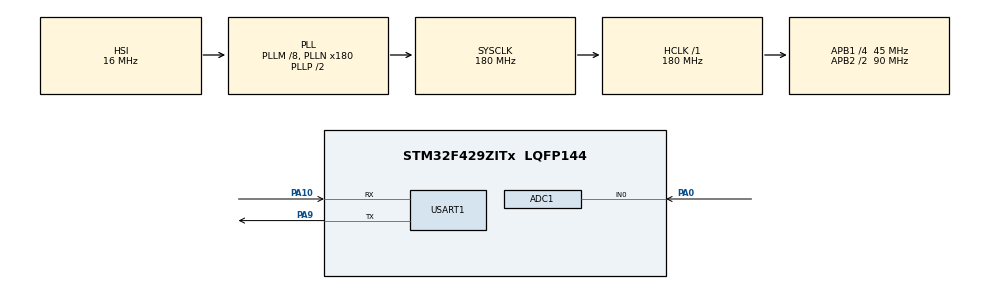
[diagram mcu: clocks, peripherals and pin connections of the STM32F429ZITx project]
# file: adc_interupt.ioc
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ADC1.Channel-0\#ChannelRegularConversion=ADC_CHANNEL_0
ADC1.NbrOfConversionFlag=1
ADC1.Rank-0\#ChannelRegularConversion=1
ADC1.SamplingTime-0\#ChannelRegularConversion=ADC_SAMPLETIME_480CYCLES
ADC1.master=1
Mcu.Family=STM32F4
Mcu.Name=STM32F429ZITx
Mcu.Package=LQFP144
NVIC.ADC_IRQn=true\:0\:0\:false\:false\:true\:true\:true\:true
NVIC.PriorityGroup=NVIC_PRIORITYGROUP_4
PA0/WKUP.Signal=ADCx_IN0
PA10.Mode=Asynchronous
PA10.Signal=USART1_RX
PA9.Mode=Asynchronous
PA9.Signal=USART1_TX
PH0/OSC_IN.Mode=HSE-External-Oscillator
PH0/OSC_IN.Signal=RCC_OSC_IN
PH1/OSC_OUT.Mode=HSE-External-Oscillator
PH1/OSC_OUT.Signal=RCC_OSC_OUT
ProjectManager.HeapSize=0x200
ProjectManager.StackSize=0x400
ProjectManager.TargetToolchain=STM32CubeIDE
RCC.48MHZClocksFreq_Value=90000000
RCC.AHBFreq_Value=180000000
RCC.APB1CLKDivider=RCC_HCLK_DIV4
RCC.APB1Freq_Value=45000000
RCC.APB1TimFreq_Value=90000000
RCC.APB2CLKDivider=RCC_HCLK_DIV2
RCC.APB2Freq_Value=90000000
RCC.APB2TimFreq_Value=180000000
RCC.CortexFreq_Value=180000000
RCC.HCLKFreq_Value=180000000
RCC.HSE_VALUE=25000000
RCC.HSI_VALUE=16000000
RCC.LSE_VALUE=32768
RCC.PLLM=8
RCC.PLLN=180
RCC.SYSCLKFreq_VALUE=180000000
RCC.SYSCLKSource=RCC_SYSCLKSOURCE_PLLCLK
RCC.VCOOutputFreq_Value=360000000
SH.ADCx_IN0.0=ADC1_IN0,IN0
USART1.VirtualMode=VM_ASYNC
board=custom

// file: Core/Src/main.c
/* USER CODE BEGIN Header */
/**
  ******************************************************************************
  * @file           : main.c
  * @brief          : Main program body
  ******************************************************************************
  * @attention
  *
  * Copyright (c) 2025 STMicroelectronics.
  * All rights reserved.
  *
  * This software is licensed under terms that can be found in the LICENSE file
  * in the root directory of this software component.
  * If no LICENSE file comes with this software, it is provided AS-IS.
  *
  ******************************************************************************
  */
/* USER CODE END Header */
#include "main.h"
#include <stdio.h>
#include <string.h> // For string manipulation

ADC_HandleTypeDef hadc1;
UART_HandleTypeDef huart1;

/* USER CODE BEGIN PV */
char uart_buffer[50]; // Buffer to store the ADC value string
uint16_t a = 0;       // Variable to hold ADC value
/* USER CODE END PV */

void SystemClock_Config(void);
static void MX_GPIO_Init(void);
static void MX_ADC1_Init(void);
static void MX_USART1_UART_Init(void);

/* USER CODE BEGIN 0 */
void HAL_ADC_ConvCpltCallback(ADC_HandleTypeDef *hadc) {
    if (hadc->Instance == ADC1) { // Check if the callback is for ADC1
        a = HAL_ADC_GetValue(hadc); // Get the ADC conversion value
        // Convert ADC value to string
        snprintf(uart_buffer, sizeof(uart_buffer), "ADC Value: %u\r\n", a);
        // Transmit the string over USART
        HAL_UART_Transmit(&huart1, (uint8_t*)uart_buffer, strlen(uart_buffer), HAL_MAX_DELAY);
    }
}
/* USER CODE END 0 */

int main(void) {
    /* MCU Configuration--------------------------------------------------------*/
    HAL_Init();
    SystemClock_Config();
    MX_GPIO_Init();
    MX_ADC1_Init();
    MX_USART1_UART_Init();

    /* USER CODE BEGIN 2 */
    HAL_ADC_Start_IT(&hadc1); // Start ADC in interrupt mode
    /* USER CODE END 2 */

    /* Infinite loop */
    while (1) {
        /* USER CODE BEGIN WHILE */
        HAL_Delay(1000); // Optional delay for testing
        /* USER CODE END WHILE */
    }
}

void SystemClock_Config(void) {
    RCC_OscInitTypeDef RCC_OscInitStruct = {0};
    RCC_ClkInitTypeDef RCC_ClkInitStruct = {0};

    __HAL_RCC_PWR_CLK_ENABLE();
    __HAL_PWR_VOLTAGESCALING_CONFIG(PWR_REGULATOR_VOLTAGE_SCALE1);

    RCC_OscInitStruct.OscillatorType = RCC_OSCILLATORTYPE_HSI;
    RCC_OscInitStruct.HSIState = RCC_HSI_ON;
    RCC_OscInitStruct.HSICalibrationValue = RCC_HSICALIBRATION_DEFAULT;
    RCC_OscInitStruct.PLL.PLLState = RCC_PLL_ON;
    RCC_OscInitStruct.PLL.PLLSource = RCC_PLLSOURCE_HSI;
    RCC_OscInitStruct.PLL.PLLM = 8;
    RCC_OscInitStruct.PLL.PLLN = 180;
    RCC_OscInitStruct.PLL.PLLP = RCC_PLLP_DIV2;
    RCC_OscInitStruct.PLL.PLLQ = 4;
    if (HAL_RCC_OscConfig(&RCC_OscInitStruct) != HAL_OK) {
        Error_Handler();
    }

    if (HAL_PWREx_EnableOverDrive() != HAL_OK) {
        Error_Handler();
    }

    RCC_ClkInitStruct.ClockType = RCC_CLOCKTYPE_HCLK | RCC_CLOCKTYPE_SYSCLK
                                  | RCC_CLOCKTYPE_PCLK1 | RCC_CLOCKTYPE_PCLK2;
    RCC_ClkInitStruct.SYSCLKSource = RCC_SYSCLKSOURCE_PLLCLK;
    RCC_ClkInitStruct.AHBCLKDivider = RCC_SYSCLK_DIV1;
    RCC_ClkInitStruct.APB1CLKDivider = RCC_HCLK_DIV4;
    RCC_ClkInitStruct.APB2CLKDivider = RCC_HCLK_DIV2;

    if (HAL_RCC_ClockConfig(&RCC_ClkInitStruct, FLASH_LATENCY_5) != HAL_OK) {
        Error_Handler();
    }
}

static void MX_ADC1_Init(void) {
    ADC_ChannelConfTypeDef sConfig = {0};
    hadc1.Instance = ADC1;
    hadc1.Init.ClockPrescaler = ADC_CLOCK_SYNC_PCLK_DIV4;
    hadc1.Init.Resolution = ADC_RESOLUTION_12B;
    hadc1.Init.ScanConvMode = DISABLE;
    hadc1.Init.ContinuousConvMode = DISABLE;
    hadc1.Init.DiscontinuousConvMode = DISABLE;
    hadc1.Init.ExternalTrigConvEdge = ADC_EXTERNALTRIGCONVEDGE_NONE;
    hadc1.Init.ExternalTrigConv = ADC_SOFTWARE_START;
    hadc1.Init.DataAlign = ADC_DATAALIGN_RIGHT;
    hadc1.Init.NbrOfConversion = 1;
    hadc1.Init.DMAContinuousRequests = DISABLE;
    hadc1.Init.EOCSelection = ADC_EOC_SINGLE_CONV;
    if (HAL_ADC_Init(&hadc1) != HAL_OK) {
        Error_Handler();
    }

    sConfig.Channel = ADC_CHANNEL_0;
    sConfig.Rank = 1;
    sConfig.SamplingTime = ADC_SAMPLETIME_480CYCLES;
    if (HAL_ADC_ConfigChannel(&hadc1, &sConfig) != HAL_OK) {
        Error_Handler();
    }
}

static void MX_USART1_UART_Init(void) {
    huart1.Instance = USART1;
    huart1.Init.BaudRate = 115200;
    huart1.Init.WordLength = UART_WORDLENGTH_8B;
    huart1.Init.StopBits = UART_STOPBITS_1;
    huart1.Init.Parity = UART_PARITY_NONE;
    huart1.Init.Mode = UART_MODE_TX_RX;
    huart1.Init.HwFlowCtl = UART_HWCONTROL_NONE;
    huart1.Init.OverSampling = UART_OVERSAMPLING_16;
    if (HAL_UART_Init(&huart1) != HAL_OK) {
        Error_Handler();
    }
}

static void MX_GPIO_Init(void) {
    __HAL_RCC_GPIOH_CLK_ENABLE();
    __HAL_RCC_GPIOA_CLK_ENABLE();
}

void Error_Handler(void) {
    __disable_irq();
    while (1) {
    }
}
